# SIDETONE_McBSP2 register map
Vendor: Texas Instruments
Peripheral module from a debugger description file (folder omap34xx).
Registers are 32-bit, access per field, reset 0x0 unless marked. A register's access mark holds for its fields unless they carry their own. Offsets are as the file gives them; lines under a group give offsets from that group; [hi:lo] are bit positions; {n}, {i} and the like mark numbered series; 'fields as' and 'values as' point back to an identical list; <NAME> marks a mode.

## SIDETONE_McBSP2
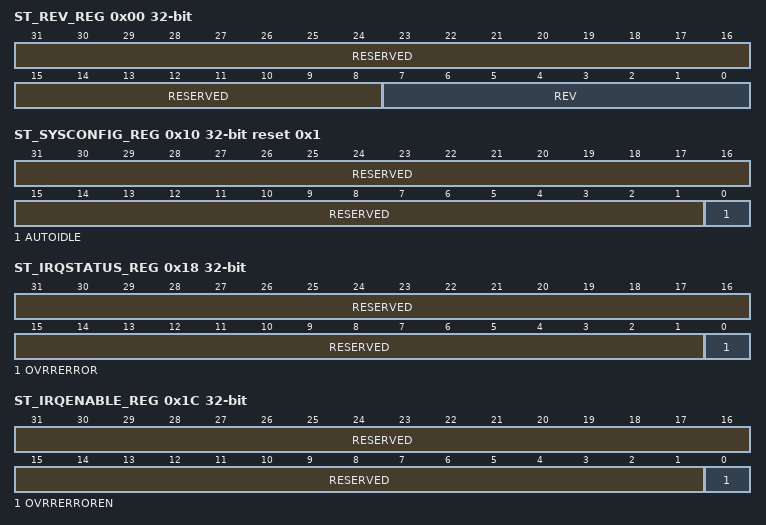
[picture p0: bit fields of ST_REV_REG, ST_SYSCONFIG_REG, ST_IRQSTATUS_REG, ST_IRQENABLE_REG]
0x00 ST_REV_REG ro (reset mask 0xFFFFFF00) — SIDETONE Revision number register
  [31:8] RESERVED — Read returns 0x0.
  [7:0] REV — IP revision[7:4] Major revision . [3:0] Minor revision . Examples: 0x10 for 1.0, 0x21 for 2.1 .
0x10 ST_SYSCONFIG_REG reset 0x1 — SIDETONE System Configuration register
  [31:1] RESERVED ro — Read returns 0x0.
  [0] AUTOIDLE rw — Automatic McBSPi_ICLK clock gating 0x0: McBSPi_ICLK clock auto-gating disabled. 0x1: McBSPi_ICLK clock auto-gating enabled.
0x18 ST_IRQSTATUS_REG — SIDETONE Interrupt Status Register
  [31:1] RESERVED ro — Read returns 0x0.
  [0] OVRRERROR rw — Over-run error has occurred. New data to be processed has arrived before the previous one has ended.Writing 1 to this bit clears the bit.
0x1C ST_IRQENABLE_REG — SIDETONE Interrupt enable register
  [31:1] RESERVED ro — Read returns 0x0.
  [0] OVRRERROREN rw — Over-run error interrupt enable bit.
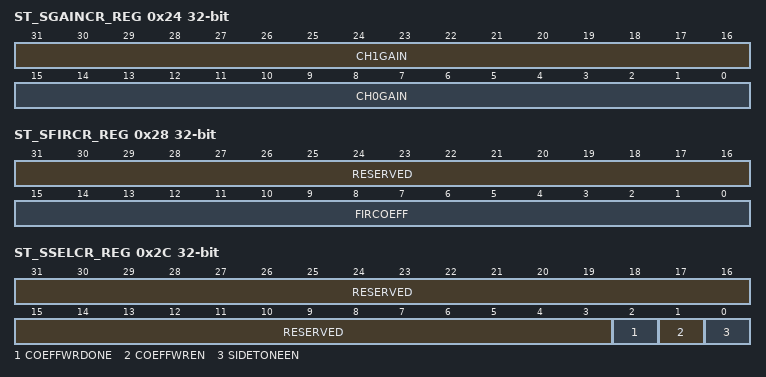
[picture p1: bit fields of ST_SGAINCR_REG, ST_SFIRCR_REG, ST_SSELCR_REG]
0x24 ST_SGAINCR_REG rw — Sidetone gain control register
  [31:16] CH1GAIN — Second sidetone channel gain
  [15:0] CH0GAIN — First sidetone channel gain
0x28 ST_SFIRCR_REG — Sidetone FIR coefficients control register
  [31:16] RESERVED ro — Read returns 0x0.
  [15:0] FIRCOEFF rw — FIR coefficients control register (the coefficients are programmed by successive write sequence of all 128 FIR coefficients)The write sequence should start with the coefficient 0.In order to enable the write to this register the COEFFWREN bit in SSELCR_REG should be set to one. When this bit is set the read operation will return only the last written value. After a complete FIR coefficients write sequence the COEFFWREN should be set to zero. . A read sequence from SFIRCR_REG while COEFFWREN is set to zero will return the coefficients values starting from 0 to 127. The write coefficient address is set to 0 by the change of COEFFWREN from 0 to 1. The read coefficient address is set to 0 by the change of COEFFWREN from 1 to 0 .
0x2C ST_SSELCR_REG — Sidetone select register
  [31:3] RESERVED ro — Read returns 0x0.
  [2] COEFFWRDONE ro — Write FIR coefficients completed.0x0: FIR coefficients not loaded0x1: FIR coefficients loaded
  [1] COEFFWREN rw — Write enable FIR coefficients.0x1:If a 0 to 1 transition on this bit occurs, the write coefficient index is reset. When this bit is 1, all coefficients can be written in SFIRCR_REG performing 128 write accesses with SIDETONEEN 1. First access writes coefficient index 0Read access in this case returns the last written value. 0x0:If a 1 to 0 transition on this bit occurs, the read coefficient index is reset. When this bit is 0, all coefficients can be read from SFIRCR_REG by performing 128 read accesses with SIDETONEEN 0. First access reads coefficient index 0.
  [0] SIDETONEEN rw — Sidetone mode enable.0x0: Sidetone disabled 0x1: Sidetone enabled
